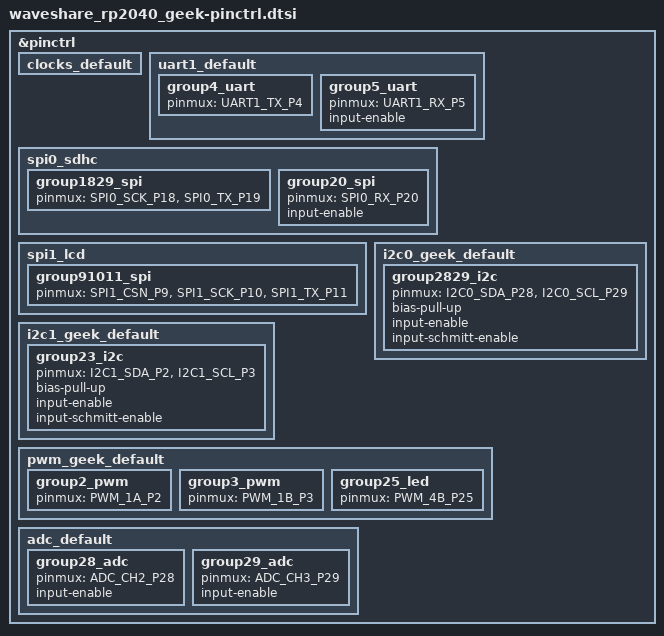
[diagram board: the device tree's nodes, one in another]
/*
 * SPDX-FileCopyrightText: Copyright (c) 2023-2026 TiaC Systems
 * SPDX-License-Identifier: Apache-2.0
 */

#include <zephyr/dt-bindings/pinctrl/rpi-pico-rp2040-pinctrl.h>

&pinctrl {
	clocks_default: clocks_default {
		/* no external clocks */
	};

	uart1_default: uart1_default {
		group4_uart {
			pinmux = <UART1_TX_P4>;		/* GP4: UART1_TX */
		};
		group5_uart {
			pinmux = <UART1_RX_P5>;		/* GP5: UART1_RX */
			input-enable;
		};
	};

	spi0_sdhc: spi0_sdhc {
		group1829_spi {
			pinmux = /* GP23 will be used as CS: <SPI0_CSN_P17>, */
				 <SPI0_SCK_P18>,	/* GP18: SPI0_SCK */
				 <SPI0_TX_P19>;		/* GP19: SPI0_TX */
		};
		group20_spi {
			pinmux = <SPI0_RX_P20>;		/* GP20: SPI0_RX */
			input-enable;
		};
	};

	spi1_lcd: spi1_lcd {
		group91011_spi {
			pinmux = <SPI1_CSN_P9>,		/* GP9: SPI1_CSN */
				 <SPI1_SCK_P10>,	/* GP10: SPI1_SCK */
				 <SPI1_TX_P11>;		/* GP11: SPI1_TX */
		};
	};

	i2c0_geek_default: i2c0_geek_default {
		group2829_i2c {
			pinmux = <I2C0_SDA_P28>,	/* GP28: I2C0_SDA */
				 <I2C0_SCL_P29>;	/* GP29: I2C0_SCL */
			bias-pull-up;
			input-enable;
			input-schmitt-enable;
		};
	};

	i2c1_geek_default: i2c1_geek_default {
		group23_i2c {
			pinmux = <I2C1_SDA_P2>,		/* GP2: I2C1_SDA */
				 <I2C1_SCL_P3>;		/* GP3: I2C1_SCL */
			bias-pull-up;
			input-enable;
			input-schmitt-enable;
		};
	};

	pwm_geek_default: pwm_geek_default {
		group2_pwm {
			pinmux = <PWM_1A_P2>;		/* GP2: PWM1CHA (2) */
		};
		group3_pwm {
			pinmux = <PWM_1B_P3>;		/* GP3: PWM1CHB (3) */
		};
		group25_led {
			pinmux = <PWM_4B_P25>;		/* GP25: PWM4CHB (9) */
		};
	};

	adc_default: adc_default {
		group28_adc {
			pinmux = <ADC_CH2_P28>;		/* GP28: ADC_CH2 */
			input-enable;
		};
		group29_adc {
			pinmux = <ADC_CH3_P29>;		/* GP29: ADC_CH3 */
			input-enable;
		};
	};
};
